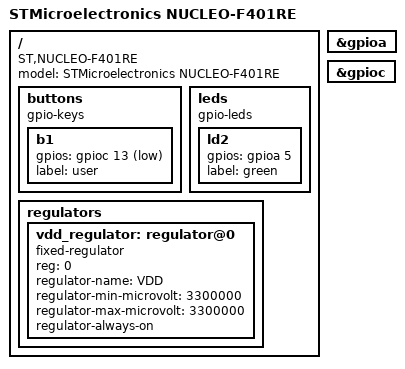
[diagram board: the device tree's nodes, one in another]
/**
 * \file
 * \brief Devicetree for NUCLEO-F401RE
 *
 * \author Copyright (C) 2017 Kamil Szczygiel http://www.distortec.com http://www.freddiechopin.info
 *
 * \par License
 * This Source Code Form is subject to the terms of the Mozilla Public License, v. 2.0. If a copy of the MPL was not
 * distributed with this file, You can obtain one at http://mozilla.org/MPL/2.0/.
 */

/dts-v1/;

#include "STM32F401RE.dtsi"

/ {
	compatible = "ST,NUCLEO-F401RE", "ST,STM32F401RE";
	model = "STMicroelectronics NUCLEO-F401RE";

	buttons {
		compatible = "gpio-keys";
		status = "okay";

		b1 {
			gpios = <&gpioc 13 1>;
			label = "user";
			status = "okay";
		};
	};

	leds {
		compatible = "gpio-leds";
		status = "okay";

		ld2 {
			gpios = <&gpioa 5 0>;
			label = "green";
			status = "okay";
		};
	};

	regulators {
		#address-cells = <1>;
		#size-cells = <0>;

		vdd_regulator: regulator@0 {
			compatible = "fixed-regulator";
			reg = <0>;
			regulator-name = "VDD";
			regulator-min-microvolt = <3300000>;
			regulator-max-microvolt = <3300000>;
			regulator-always-on;
		};
	};
};

&gpioa {
	status = "okay";
};

&gpioc {
	status = "okay";
};
